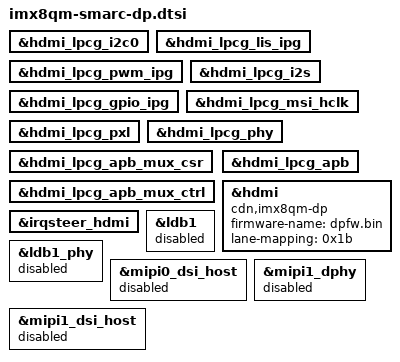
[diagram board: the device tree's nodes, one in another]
/*
 * Copyright 2023 EMBEDIAN, INC.
 */

&hdmi_lpcg_i2c0 {
	status = "okay";
};

&hdmi_lpcg_lis_ipg {
	status = "okay";
};

&hdmi_lpcg_pwm_ipg {
	status = "okay";
};

&hdmi_lpcg_i2s {
	status = "okay";
};

&hdmi_lpcg_gpio_ipg {
	status = "okay";
};

&hdmi_lpcg_msi_hclk {
	status = "okay";
};

&hdmi_lpcg_pxl {
	status = "okay";
};

&hdmi_lpcg_phy {
	status = "okay";
};

&hdmi_lpcg_apb_mux_csr {
	status = "okay";
};

&hdmi_lpcg_apb_mux_ctrl {
	status = "okay";
};

&hdmi_lpcg_apb {
	status = "okay";
};

&hdmi {
	compatible = "cdn,imx8qm-dp";
	firmware-name = "dpfw.bin";
	lane-mapping = <0x1b>;
	status = "okay";
};

&irqsteer_hdmi {
	status = "okay";
};

&ldb1_phy {
	status = "disabled";
};

&ldb1 {
	status = "disabled";
};

&mipi0_dsi_host {
	status = "disabled";
};

&mipi1_dphy {
	status = "disabled";
};

&mipi1_dsi_host {
	status = "disabled";
};

&mipi1_dphy {
	status = "disabled";
};
